# ELM register map
Vendor: Texas Instruments
Peripheral module from a debugger description file (folder am335x).
Registers are 32-bit, read-only, no defined reset value unless marked. A register's access mark holds for its fields unless they carry their own. Offsets are as the file gives them; lines under a group give offsets from that group; [hi:lo] are bit positions; {n}, {i} and the like mark numbered series; 'fields as' and 'values as' point back to an identical list; <NAME> marks a mode.

## ELM
0x00 ELM_REVISION — This register contains the IP revision code.
  [31:0] REVISION — IP Revision, value 0 to FFFF FFFFh.
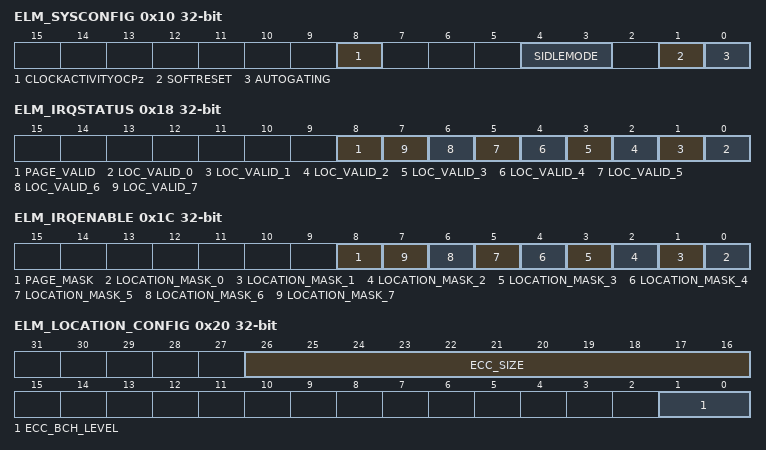
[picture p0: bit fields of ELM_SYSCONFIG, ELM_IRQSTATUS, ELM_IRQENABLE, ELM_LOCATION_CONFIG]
0x10 ELM_SYSCONFIG access per field — This register allows controlling various parameters of the OCP interface.
  [8] CLOCKACTIVITYOCPz rw — OCP Clock activity when module is in IDLE mode (during wake up mode period).
  [4:3] SIDLEMODE rw — Slave interface power management (IDLE req/ack control).
  [1] SOFTRESET rw — Module software reset. This bit is automatically reset by hardware (During reads, it always returns 0.). It has same effect as the OCP hardware reset.
  [0] AUTOGATING rw — Internal OCP clock gating strategy. (No module visible impact other than saving power.)
0x14 ELM_SYSSTATUS
  [0] RESETDONE — Internal reset monitoring (OCP domain). Undefined since: From hardware perspective, the reset state is 0. From software user perspective, when the accessible module is 1.
0x18 ELM_IRQSTATUS access per field — This register doubles as a status register for the error-location processes.
  [8] PAGE_VALID rw — Error-location status for a full page, based on the mask definition.
  [n] LOC_VALID_{n} rw (n=0..7) — Error-location status for syndrome polynomial {n}.
0x1C ELM_IRQENABLE access per field
  [8] PAGE_MASK rw — Page interrupt mask bit
  [n] LOCATION_MASK_{n} rw (n=0..7) — Error-location interrupt mask bit for syndrome polynomial {n}.
0x20 ELM_LOCATION_CONFIG access per field
  [26:16] ECC_SIZE rw — Maximum size of the buffers for which the error-location engine is used, in number of nibbles (4 bits entities), value 0 to 7FFh.
  [1:0] ECC_BCH_LEVEL rw — Error correction level.
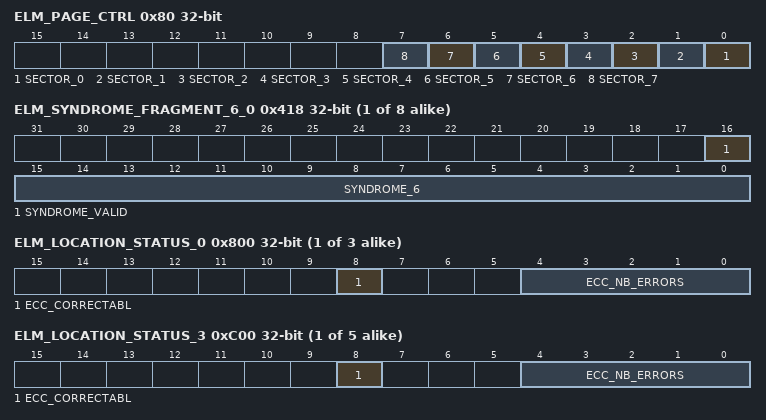
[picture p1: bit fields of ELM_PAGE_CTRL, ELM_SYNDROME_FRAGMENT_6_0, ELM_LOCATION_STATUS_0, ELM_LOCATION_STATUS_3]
0x80 ELM_PAGE_CTRL access per field
  [n] SECTOR_{n} rw (n=0..7) — Set to 1 if syndrome polynomial {n} is part of the page in page mode. Must be 0 in continuous mode.
{0x400+0x40*i} ELM_SYNDROME_FRAGMENT_0_{i} rw (i=0..7)
  [31:0] SYNDROME_0 — Syndrome bits 0 to 31, value 0 to FFFF FFFFh.
{0x404+0x40*i} ELM_SYNDROME_FRAGMENT_1_{i} rw (i=0..7)
  [31:0] SYNDROME_1 — Syndrome bits 32 to 63, value 0 to FFFF FFFFh.
{0x408+0x40*i} ELM_SYNDROME_FRAGMENT_2_{i} rw (i=0..7)
  [31:0] SYNDROME_2 — Syndrome bits 64 to 95, value 0 to FFFF FFFFh.
{0x40C+0x40*i} ELM_SYNDROME_FRAGMENT_3_{i} rw (i=0..7)
  [31:0] SYNDROME_3 — Syndrome bits 96 to 127, value 0 to FFFF FFFFh.
{0x410+0x40*i} ELM_SYNDROME_FRAGMENT_4_{i} rw (i=0..7)
  [31:0] SYNDROME_4 — Syndrome bits 128 to 159, value 0 to FFFF FFFFh.
{0x414+0x40*i} ELM_SYNDROME_FRAGMENT_5_{i} rw (i=0..7)
  [31:0] SYNDROME_5 — Syndrome bits 160 to 191, value 0 to FFFF FFFFh.
{0x418+0x40*i} ELM_SYNDROME_FRAGMENT_6_{i} access per field (i=0..7)
  [16] SYNDROME_VALID rw — Syndrome valid bit.
  [15:0] SYNDROME_6 rw — Syndrome bits 192 to 207, value 0 to FFFFh.
{0x800+0x100*i} ELM_LOCATION_STATUS_{i} (i=0..2)
  [8] ECC_CORRECTABL — Error-location process exit status.
  [4:0] ECC_NB_ERRORS — Number of errors detected and located, value 0 to 1Fh.
{0x880+4i} ELM_ERROR_LOCATION_{i}_0 (i=0..15)
  [12:0] ECC_ERROR_LOCATION — Error-location bit address, 0 to 1FFFh.
{0x980+4i} ELM_ERROR_LOCATION_{i}_1 (i=0..15)
  [12:0] ECC_ERROR_LOCATION — Error-location bit address, 0 to 1FFFh.
{0xA80+4i} ELM_ERROR_LOCATION_{i}_2 (i=0..15)
  [12:0] ECC_ERROR_LOCATION — Error-location bit address, 0 to 1FFFh.
{0xB80+4i} ELM_ERROR_LOCATION_{i}_3 (i=0..15)
  [12:0] ECC_ERROR_LOCATION — Error-location bit address, 0 to 1FFFh.
{0x600+0x200*i} ELM_LOCATION_STATUS_{i} (i=3..7)
  fields as ELM_LOCATION_STATUS_0
{0xC80+4i} ELM_ERROR_LOCATION_{i}_4 (i=0..15)
  [12:0] ECC_ERROR_LOCATION — Error-location bit address, 0 to 1FFFh.
{0xD80+4i} ELM_ERROR_LOCATION_{i}_5 (i=0..15)
  [12:0] ECC_ERROR_LOCATION — Error-location bit address, 0 to 1FFFh.
{0xE80+4i} ELM_ERROR_LOCATION_{i}_6 (i=0..15)
  [12:0] ECC_ERROR_LOCATION — Error-location bit address, 0 to 1FFFh.
{0xF80+4i} ELM_ERROR_LOCATION_{i}_7 (i=0..15)
  [12:0] ECC_ERROR_LOCATION — Error-location bit address, 0 to 1FFFh.
